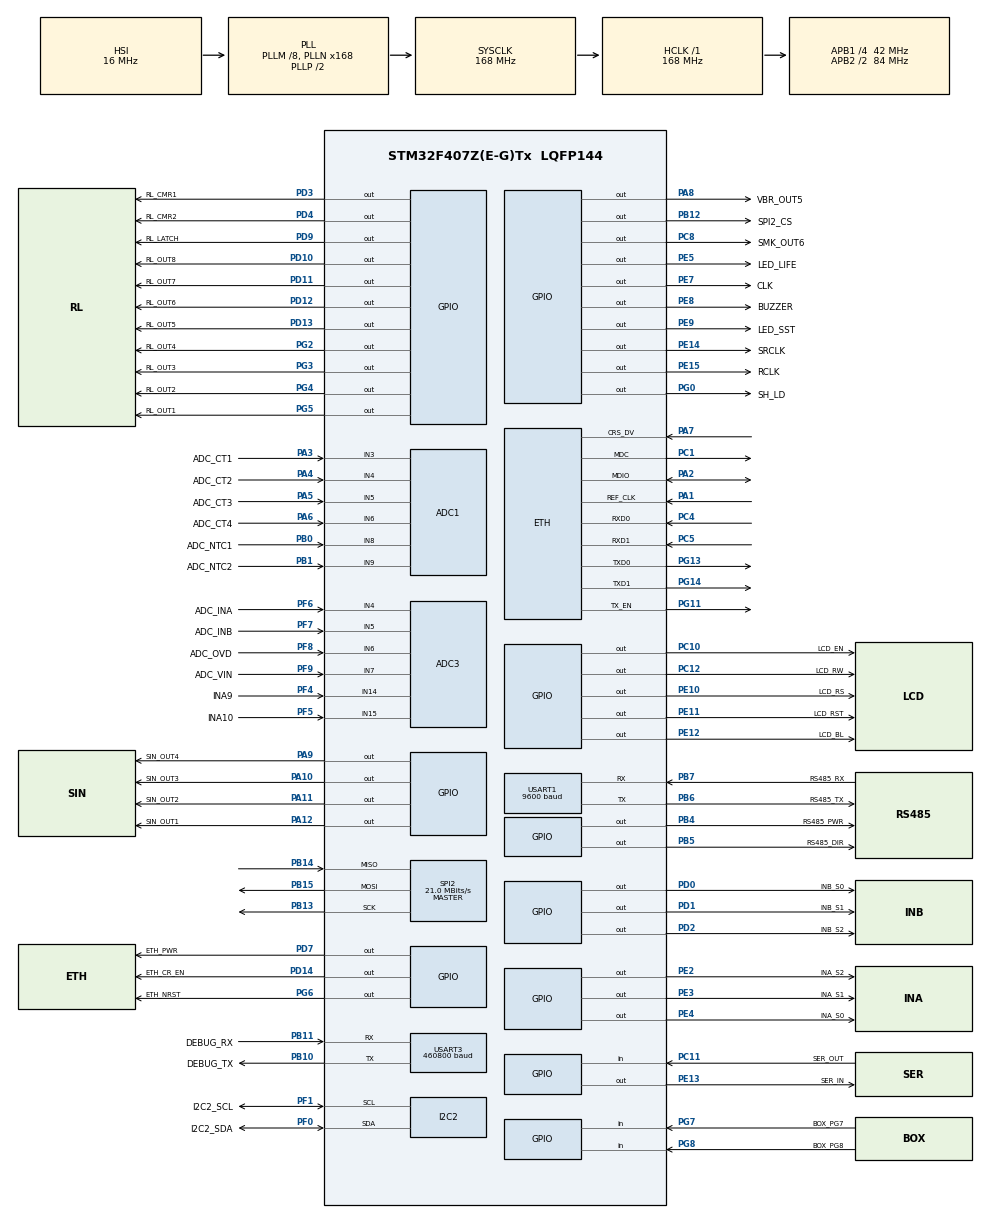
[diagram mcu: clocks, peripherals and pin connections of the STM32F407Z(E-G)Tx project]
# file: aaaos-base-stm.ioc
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ADC1.Channel-1\#ChannelRegularConversion=ADC_CHANNEL_8
ADC1.NbrOfConversionFlag=1
ADC1.Rank-1\#ChannelRegularConversion=1
ADC1.SamplingTime-1\#ChannelRegularConversion=ADC_SAMPLETIME_3CYCLES
ADC1.master=1
ADC3.Channel-0\#ChannelRegularConversion=ADC_CHANNEL_4
ADC3.NbrOfConversionFlag=1
ADC3.Rank-0\#ChannelRegularConversion=1
ADC3.SamplingTime-0\#ChannelRegularConversion=ADC_SAMPLETIME_3CYCLES
ETH.MediaInterface=HAL_ETH_RMII_MODE
ETH.PHY_READ_TO=0x0004FFFF
ETH.PHY_WRITE_TO=0x0004FFFF
ETH.PhyAddress=0
FREERTOS.HEAP_NUMBER=4
FREERTOS.Tasks01=defaultTask,24,256,StartDefaultTask,Default,NULL,Dynamic,NULL,NULL
FREERTOS.configCHECK_FOR_STACK_OVERFLOW=1
FREERTOS.configTOTAL_HEAP_SIZE=65536
FREERTOS.configUSE_MALLOC_FAILED_HOOK=1
FREERTOS.configUSE_NEWLIB_REENTRANT=1
IWDG.Prescaler=IWDG_PRESCALER_256
LWIP.BSP.number=1
LWIP.GATEWAY_ADDRESS=192.168.001.001
LWIP.IP_ADDRESS=192.168.001.009
LWIP.LWIP_DHCP=1
LWIP.LWIP_DNS=1
LWIP.LWIP_NETIF_HOSTNAME=0
LWIP.LWIP_NETIF_LINK_CALLBACK=0
LWIP.LWIP_NETIF_STATUS_CALLBACK=1
LWIP.LWIP_SNTP=1
LWIP.LWIP_TIMERS_CUSTOM=0
LWIP.MEMP_MEM_INIT=0
LWIP.MEMP_MEM_MALLOC=0
LWIP.MEMP_NUM_SYS_TIMEOUT=12
LWIP.MEM_LIBC_MALLOC=0
LWIP.MEM_SIZE=2048
LWIP.NETMASK_ADDRESS=255.255.255.000
LWIP.TCPIP_THREAD_STACKSIZE=2048
LWIP.Version=v2.1.2_Cube
LWIP0.BSP.STBoard=false
LWIP0.BSP.api=BSP_COMPONENT_DRIVER
LWIP0.BSP.component=LAN8742
LWIP0.BSP.instance=LAN8742
LWIP0.BSP.name=Driver_PHY
LWIP0.BSP.semaphore=S_LAN8742
LWIP0.BSP.solution=LAN8742
Mcu.Family=STM32F4
Mcu.Name=STM32F407Z(E-G)Tx
Mcu.Package=LQFP144
NVIC.ETH_IRQn=true\:5\:0\:false\:false\:true\:true\:false\:true\:true
NVIC.PriorityGroup=NVIC_PRIORITYGROUP_4
NVIC.TIM6_DAC_IRQn=true\:0\:0\:false\:false\:true\:false\:false\:true\:true
NVIC.TimeBase=TIM6_DAC_IRQn
NVIC.TimeBaseIP=TIM6
NVIC.USART1_IRQn=true\:9\:0\:true\:false\:true\:true\:true\:true\:true
NVIC.USART3_IRQn=true\:10\:0\:true\:false\:true\:true\:true\:true\:true
PA1.Mode=RMII
PA1.Signal=ETH_REF_CLK
PA10.GPIO_Label=SIN_OUT3
PA10.Signal=GPIO_Output
PA11.GPIO_Label=SIN_OUT2
PA11.Signal=GPIO_Output
PA12.GPIO_Label=SIN_OUT1
PA12.Signal=GPIO_Output
PA2.Mode=RMII
PA2.Signal=ETH_MDIO
PA3.GPIO_Label=ADC_CT1
PA3.Signal=ADCx_IN3
PA4.GPIO_Label=ADC_CT2
PA4.Signal=ADCx_IN4
PA5.GPIO_Label=ADC_CT3
PA5.Signal=ADCx_IN5
PA6.GPIO_Label=ADC_CT4
PA6.Signal=ADCx_IN6
PA7.Mode=RMII
PA7.Signal=ETH_CRS_DV
PA8.GPIO_Label=VBR_OUT5
PA8.Signal=GPIO_Output
PA9.GPIO_Label=SIN_OUT4
PA9.Signal=GPIO_Output
PB0.GPIO_Label=ADC_NTC1
PB0.Signal=ADCx_IN8
PB1.GPIO_Label=ADC_NTC2
PB1.Signal=ADCx_IN9
PB10.GPIO_Label=DEBUG_TX
PB10.Mode=Asynchronous
PB10.Signal=USART3_TX
PB11.GPIO_Label=DEBUG_RX
PB11.Mode=Asynchronous
PB11.Signal=USART3_RX
PB12.GPIO_Label=SPI2_CS
PB12.PinState=GPIO_PIN_SET
PB12.Signal=GPIO_Output
PB13.Mode=Full_Duplex_Master
PB13.Signal=SPI2_SCK
PB14.Mode=Full_Duplex_Master
PB14.Signal=SPI2_MISO
PB15.Mode=Full_Duplex_Master
PB15.Signal=SPI2_MOSI
PB4.GPIO_Label=RS485_PWR
PB4.Signal=GPIO_Output
PB5.GPIO_Label=RS485_DIR
PB5.Signal=GPIO_Output
PB6.GPIO_Label=RS485_TX
PB6.Mode=Asynchronous
PB6.Signal=USART1_TX
PB7.GPIO_Label=RS485_RX
PB7.Mode=Asynchronous
PB7.Signal=USART1_RX
PC1.Mode=RMII
PC1.Signal=ETH_MDC
PC10.GPIO_Label=LCD_EN
PC10.GPIO_Speed=GPIO_SPEED_FREQ_LOW
PC10.Signal=GPIO_Output
PC11.GPIO_Label=SER_OUT
PC11.Signal=GPIO_Input
PC12.GPIO_Label=LCD_RW
PC12.GPIO_Speed=GPIO_SPEED_FREQ_LOW
PC12.Signal=GPIO_Output
PC14-OSC32_IN.Mode=LSE-External-Oscillator
PC14-OSC32_IN.Signal=RCC_OSC32_IN
PC15-OSC32_OUT.Mode=LSE-External-Oscillator
PC15-OSC32_OUT.Signal=RCC_OSC32_OUT
PC4.Mode=RMII
PC4.Signal=ETH_RXD0
PC5.Mode=RMII
PC5.Signal=ETH_RXD1
PC8.GPIO_Label=SMK_OUT6
PC8.Signal=GPIO_Output
PD0.GPIO_Label=INB_S0
PD0.Signal=GPIO_Output
PD1.GPIO_Label=INB_S1
PD1.Signal=GPIO_Output
PD10.GPIO_Label=RL_OUT8
PD10.Signal=GPIO_Output
PD11.GPIO_Label=RL_OUT7
PD11.Signal=GPIO_Output
PD12.GPIO_Label=RL_OUT6
PD12.Signal=GPIO_Output
PD13.GPIO_Label=RL_OUT5
PD13.Signal=GPIO_Output
PD14.GPIO_Label=ETH_CR_EN
PD14.PinState=GPIO_PIN_SET
PD14.Signal=GPIO_Output
PD2.GPIO_Label=INB_S2
PD2.Signal=GPIO_Output
PD3.GPIO_Label=RL_CMR1
PD3.Signal=GPIO_Output
PD4.GPIO_Label=RL_CMR2
PD4.Signal=GPIO_Output
PD7.GPIO_Label=ETH_PWR
PD7.PinState=GPIO_PIN_SET
PD7.Signal=GPIO_Output
PD9.GPIO_Label=RL_LATCH
PD9.Signal=GPIO_Output
PE10.GPIO_Label=LCD_RS
PE10.GPIO_Speed=GPIO_SPEED_FREQ_LOW
PE10.PinState=GPIO_PIN_SET
PE10.Signal=GPIO_Output
PE11.GPIO_Label=LCD_RST
PE11.PinState=GPIO_PIN_RESET
PE11.Signal=GPIO_Output
PE12.GPIO_Label=LCD_BL
PE12.PinState=GPIO_PIN_SET
PE12.Signal=GPIO_Output
PE13.GPIO_Label=SER_IN
PE13.Signal=GPIO_Output
PE14.GPIO_Label=SRCLK
PE14.Signal=GPIO_Output
PE15.GPIO_Label=RCLK
PE15.Signal=GPIO_Output
PE2.GPIO_Label=INA_S2
PE2.Signal=GPIO_Output
PE3.GPIO_Label=INA_S1
PE3.Signal=GPIO_Output
PE4.GPIO_Label=INA_S0
PE4.Signal=GPIO_Output
PE5.GPIO_Label=LED_LIFE
PE5.PinState=GPIO_PIN_SET
PE5.Signal=GPIO_Output
PE7.GPIO_Label=CLK
PE7.Signal=GPIO_Output
PE8.GPIO_Label=BUZZER
PE8.Signal=GPIO_Output
PE9.GPIO_Label=LED_SST
PE9.Signal=GPIO_Output
PF0.GPIO_Label=I2C2_SDA
PF0.Mode=I2C
PF0.Signal=I2C2_SDA
PF1.GPIO_Label=I2C2_SCL
PF1.Mode=I2C
PF1.Signal=I2C2_SCL
PF4.GPIO_Label=INA9
PF4.Mode=IN14
PF4.Signal=ADC3_IN14
PF5.GPIO_Label=INA10
PF5.Mode=IN15
PF5.Signal=ADC3_IN15
PF6.GPIO_Label=ADC_INA
PF6.Mode=IN4
PF6.Signal=ADC3_IN4
PF7.GPIO_Label=ADC_INB
PF7.Mode=IN5
PF7.Signal=ADC3_IN5
PF8.GPIO_Label=ADC_OVD
PF8.Mode=IN6
PF8.Signal=ADC3_IN6
PF9.GPIO_Label=ADC_VIN
PF9.Mode=IN7
PF9.Signal=ADC3_IN7
PG0.GPIO_Label=SH_LD
PG0.Signal=GPIO_Output
PG11.Mode=RMII
PG11.Signal=ETH_TX_EN
PG13.Mode=RMII
PG13.Signal=ETH_TXD0
PG14.Mode=RMII
PG14.Signal=ETH_TXD1
PG2.GPIO_Label=RL_OUT4
PG2.Signal=GPIO_Output
PG3.GPIO_Label=RL_OUT3
PG3.Signal=GPIO_Output
PG4.GPIO_Label=RL_OUT2
PG4.Signal=GPIO_Output
PG5.GPIO_Label=RL_OUT1
PG5.Signal=GPIO_Output
PG6.GPIO_Label=ETH_NRST
PG6.PinState=GPIO_PIN_SET
PG6.Signal=GPIO_Output
PG7.GPIO_Label=BOX_PG7
PG7.Signal=GPIO_Input
PG8.GPIO_Label=BOX_PG8
PG8.Signal=GPIO_Input
PH0-OSC_IN.Mode=HSE-External-Oscillator
PH0-OSC_IN.Signal=RCC_OSC_IN
PH1-OSC_OUT.Mode=HSE-External-Oscillator
PH1-OSC_OUT.Signal=RCC_OSC_OUT
ProjectManager.HeapSize=0x200
ProjectManager.StackSize=0x400
ProjectManager.TargetToolchain=STM32CubeIDE
RCC.48MHZClocksFreq_Value=48000000
RCC.AHBFreq_Value=168000000
RCC.APB1CLKDivider=RCC_HCLK_DIV4
RCC.APB1Freq_Value=42000000
RCC.APB1TimFreq_Value=84000000
RCC.APB2CLKDivider=RCC_HCLK_DIV2
RCC.APB2Freq_Value=84000000
RCC.APB2TimFreq_Value=168000000
RCC.CortexFreq_Value=168000000
RCC.HCLKFreq_Value=168000000
RCC.HSE_VALUE=25000000
RCC.HSI_VALUE=16000000
RCC.PLLM=8
RCC.PLLN=168
RCC.PLLQ=7
RCC.RCC_RTC_Clock_Source=RCC_RTCCLKSOURCE_LSE
RCC.RCC_RTC_Clock_SourceVirtual=RCC_RTCCLKSOURCE_LSE
RCC.SYSCLKFreq_VALUE=168000000
RCC.SYSCLKSource=RCC_SYSCLKSOURCE_PLLCLK
RCC.VCOOutputFreq_Value=336000000
RTC.Format=RTC_FORMAT_BIN
SH.ADCx_IN3.0=ADC1_IN3,IN3
SH.ADCx_IN4.0=ADC1_IN4,IN4
SH.ADCx_IN5.0=ADC1_IN5,IN5
SH.ADCx_IN6.0=ADC1_IN6,IN6
SH.ADCx_IN8.0=ADC1_IN8,IN8
SH.ADCx_IN9.0=ADC1_IN9,IN9
SPI2.CalculateBaudRate=21.0 MBits/s
SPI2.Direction=SPI_DIRECTION_2LINES
SPI2.Mode=SPI_MODE_MASTER
SPI2.VirtualType=VM_MASTER
USART1.BaudRate=9600
USART1.VirtualMode=VM_ASYNC
USART3.BaudRate=460800
USART3.VirtualMode=VM_ASYNC
VP_FREERTOS_VS_CMSIS_V2.Mode=CMSIS_V2
VP_IWDG_VS_IWDG.Mode=IWDG_Activate
VP_LWIP_VS_Enabled.Mode=Enabled
VP_RNG_VS_RNG.Mode=RNG_Activate
VP_RTC_VS_RTC_Activate.Mode=RTC_Enabled
VP_RTC_VS_RTC_Calendar.Mode=RTC_Calendar
VP_SYS_VS_tim6.Mode=TIM6
board=custom

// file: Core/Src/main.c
/* USER CODE BEGIN Header */
/**
 ******************************************************************************
 * @file           : main.c
 * @brief          : Main program body
 ******************************************************************************
 * @attention
 *
 * <h2><center>&copy; Copyright (c) 2022 STMicroelectronics.
 * All rights reserved.</center></h2>
 *
 * This software component is licensed by ST under Ultimate Liberty license
 * SLA0044, the "License"; You may not use this file except in compliance with
 * the License. You may obtain a copy of the License at:
 *                             www.st.com/SLA0044
 *
 ******************************************************************************
 */
/* USER CODE END Header */
#include "main.h"
#include "cmsis_os.h"
#include "adc.h"
#include "i2c.h"
#include "iwdg.h"
#include "lwip.h"
#include "rng.h"
#include "rtc.h"
#include "spi.h"
#include "usart.h"
#include "gpio.h"

/* USER CODE BEGIN Includes */
#include "sys_log.h"
/* USER CODE END Includes */

void SystemClock_Config(void);
void MX_FREERTOS_Init(void);

int main(void)
{

  /* MCU Configuration--------------------------------------------------------*/

  /* Reset of all peripherals, Initializes the Flash interface and the Systick. */
  HAL_Init();

  /* Configure the system clock */
  SystemClock_Config();

  /* Initialize all configured peripherals */
  MX_GPIO_Init();
  MX_SPI2_Init();
  MX_USART3_UART_Init();
  MX_RNG_Init();
  MX_ADC1_Init();
  MX_ADC3_Init();
  MX_I2C2_Init();
  MX_USART1_UART_Init();
  MX_RTC_Init();
  MX_IWDG_Init();
  /* USER CODE BEGIN 2 */
	printf(ESCAPE RESET_COLOR "Start printf redirect\r\n");
	/* Turn on Ethernet power */
	hwEthernetReboot();
  /* USER CODE END 2 */

  /* Init scheduler */
  osKernelInitialize();  /* Call init function for freertos objects (in freertos.c) */
  MX_FREERTOS_Init();

  /* Start scheduler */
  osKernelStart();

  /* We should never get here as control is now taken by the scheduler */
  /* Infinite loop */
	while (1) {

	}
}

void SystemClock_Config(void)
{
  RCC_OscInitTypeDef RCC_OscInitStruct = {0};
  RCC_ClkInitTypeDef RCC_ClkInitStruct = {0};

  /** Configure the main internal regulator output voltage
  */
  __HAL_RCC_PWR_CLK_ENABLE();
  __HAL_PWR_VOLTAGESCALING_CONFIG(PWR_REGULATOR_VOLTAGE_SCALE1);

  /** Initializes the RCC Oscillators according to the specified parameters
  * in the RCC_OscInitTypeDef structure.
  */
  RCC_OscInitStruct.OscillatorType = RCC_OSCILLATORTYPE_HSI|RCC_OSCILLATORTYPE_LSI
                              |RCC_OSCILLATORTYPE_LSE;
  RCC_OscInitStruct.LSEState = RCC_LSE_ON;
  RCC_OscInitStruct.HSIState = RCC_HSI_ON;
  RCC_OscInitStruct.HSICalibrationValue = RCC_HSICALIBRATION_DEFAULT;
  RCC_OscInitStruct.LSIState = RCC_LSI_ON;
  RCC_OscInitStruct.PLL.PLLState = RCC_PLL_ON;
  RCC_OscInitStruct.PLL.PLLSource = RCC_PLLSOURCE_HSI;
  RCC_OscInitStruct.PLL.PLLM = 8;
  RCC_OscInitStruct.PLL.PLLN = 168;
  RCC_OscInitStruct.PLL.PLLP = RCC_PLLP_DIV2;
  RCC_OscInitStruct.PLL.PLLQ = 7;
  if (HAL_RCC_OscConfig(&RCC_OscInitStruct) != HAL_OK)
  {
    Error_Handler();
  }

  /** Initializes the CPU, AHB and APB buses clocks
  */
  RCC_ClkInitStruct.ClockType = RCC_CLOCKTYPE_HCLK|RCC_CLOCKTYPE_SYSCLK
                              |RCC_CLOCKTYPE_PCLK1|RCC_CLOCKTYPE_PCLK2;
  RCC_ClkInitStruct.SYSCLKSource = RCC_SYSCLKSOURCE_PLLCLK;
  RCC_ClkInitStruct.AHBCLKDivider = RCC_SYSCLK_DIV1;
  RCC_ClkInitStruct.APB1CLKDivider = RCC_HCLK_DIV4;
  RCC_ClkInitStruct.APB2CLKDivider = RCC_HCLK_DIV2;

  if (HAL_RCC_ClockConfig(&RCC_ClkInitStruct, FLASH_LATENCY_5) != HAL_OK)
  {
    Error_Handler();
  }
}

void HAL_TIM_PeriodElapsedCallback(TIM_HandleTypeDef *htim)
{
  if (htim->Instance == TIM6) {
    HAL_IncTick();
  }
}

void Error_Handler(void)
{
  /* USER CODE BEGIN Error_Handler_Debug */
	FATAL("HW1");
  /* USER CODE END Error_Handler_Debug */
}

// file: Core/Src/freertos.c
/* USER CODE BEGIN Header */
/**
 ******************************************************************************
 * File Name          : freertos.c
 * Description        : Code for freertos applications
 ******************************************************************************
 * @attention
 *
 * <h2><center>&copy; Copyright (c) 2022 STMicroelectronics.
 * All rights reserved.</center></h2>
 *
 * This software component is licensed by ST under Ultimate Liberty license
 * SLA0044, the "License"; You may not use this file except in compliance with
 * the License. You may obtain a copy of the License at:
 *                             www.st.com/SLA0044
 *
 ******************************************************************************
 */
/* USER CODE END Header */

#include "FreeRTOS.h"
#include "task.h"
#include "main.h"
#include "cmsis_os.h"

/* USER CODE BEGIN Includes */
#include "aaa.h"
#include "sys_log.h"
#include "sys_io.h"
/* USER CODE END Includes */

/* Definitions for defaultTask */
osThreadId_t defaultTaskHandle;
const osThreadAttr_t defaultTask_attributes = {
  .name = "defaultTask",
  .stack_size = 256 * 4,
  .priority = (osPriority_t) osPriorityNormal,
};

void StartDefaultTask(void *argument);

extern void MX_LWIP_Init(void);
void MX_FREERTOS_Init(void); /* (MISRA C 2004 rule 8.1) */

/* Hook prototypes */
void vApplicationStackOverflowHook(xTaskHandle xTask, signed char *pcTaskName);
void vApplicationMallocFailedHook(void);

/* USER CODE BEGIN 4 */
void vApplicationStackOverflowHook(xTaskHandle xTask, signed char *pcTaskName) {
	/* Run time stack overflow checking is performed if
	 configCHECK_FOR_STACK_OVERFLOW is defined to 1 or 2. This hook function is
	 called if a stack overflow is detected. */
	FATAL("StackOverflow");
}
/* USER CODE END 4 */

/* USER CODE BEGIN 5 */
void vApplicationMallocFailedHook(void) {
	/* vApplicationMallocFailedHook() will only be called if
	 configUSE_MALLOC_FAILED_HOOK is set to 1 in FreeRTOSConfig.h. It is a hook
	 function that will get called if a call to pvPortMalloc() fails.
	 pvPortMalloc() is called internally by the kernel whenever a task, queue,
	 timer or semaphore is created. It is also called by various parts of the
	 demo application. If heap_1.c or heap_2.c are used, then the size of the
	 heap available to pvPortMalloc() is defined by configTOTAL_HEAP_SIZE in
	 FreeRTOSConfig.h, and the xPortGetFreeHeapSize() API function can be used
	 to query the size of free heap space that remains (although it does not
	 provide information on how the remaining heap might be fragmented). */
	FATAL("MallocFailed");
}
/* USER CODE END 5 */

void MX_FREERTOS_Init(void) {
  /* USER CODE BEGIN Init */
	AAAOS();
  /* USER CODE END Init */

  /* Create the thread(s) */
  /* creation of defaultTask */
  defaultTaskHandle = osThreadNew(StartDefaultTask, NULL, &defaultTask_attributes);

}

void StartDefaultTask(void *argument)
{
  /* init code for LWIP */
  MX_LWIP_Init();
  /* USER CODE BEGIN StartDefaultTask */
	vTaskDelete(NULL);
	/* Infinite loop */
	for (;;) {
		vTaskDelay(portMAX_DELAY);
	}

  /* USER CODE END StartDefaultTask */
}
